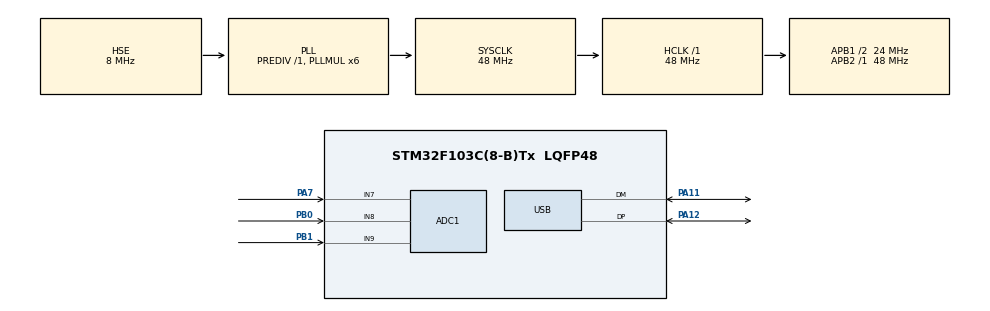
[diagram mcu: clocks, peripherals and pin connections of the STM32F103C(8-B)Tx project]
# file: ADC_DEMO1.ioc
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Mcu.Family=STM32F1
RCC.PLLSourceVirtual=RCC_PLLSOURCE_HSE
USB_DEVICE.CLASS_NAME_FS=CDC
Dma.ADC1.0.Instance=DMA1_Channel1
ADC1.Rank-0\#ChannelRegularConversion=1
PD1-OSC_OUT.Mode=HSE-External-Oscillator
ADC1.ContinuousConvMode=ENABLE
USB_DEVICE.VirtualModeFS=Cdc_FS
PA11.Mode=Device
PD0-OSC_IN.Signal=RCC_OSC_IN
RCC.APB1CLKDivider=RCC_HCLK_DIV2
ADC1.SamplingTime-2\#ChannelRegularConversion=ADC_SAMPLETIME_55CYCLES_5
RCC.SYSCLKSource=RCC_SYSCLKSOURCE_PLLCLK
ProjectManager.StackSize=0x400
PD1-OSC_OUT.Signal=RCC_OSC_OUT
RCC.ADCPresc=RCC_ADCPCLK2_DIV4
PA13.Signal=SYS_JTMS-SWDIO
Dma.ADC1.0.PeriphDataAlignment=DMA_PDATAALIGN_WORD
PA12.Signal=USB_DP
ProjectManager.TargetToolchain=STM32CubeIDE
Dma.ADC1.0.Mode=DMA_CIRCULAR
SH.ADCx_IN7.0=ADC1_IN7,IN7
RCC.HCLKFreq_Value=48000000
VP_USB_DEVICE_VS_USB_DEVICE_CDC_FS.Mode=CDC_FS
Dma.ADC1.0.Priority=DMA_PRIORITY_MEDIUM
RCC.APB2TimFreq_Value=48000000
ADC1.Channel-1\#ChannelRegularConversion=ADC_CHANNEL_9
Dma.ADC1.0.Direction=DMA_PERIPH_TO_MEMORY
ADC1.Channel-2\#ChannelRegularConversion=ADC_CHANNEL_7
RCC.USBFreq_Value=48000000
Dma.ADC1.0.MemDataAlignment=DMA_MDATAALIGN_WORD
RCC.AHBFreq_Value=48000000
PD0-OSC_IN.Mode=HSE-External-Oscillator
ADC1.Channel-0\#ChannelRegularConversion=ADC_CHANNEL_8
board=custom
RCC.PLLMUL=RCC_PLL_MUL6
RCC.APB2Freq_Value=48000000
ADC1.Rank-2\#ChannelRegularConversion=3
PA14.Mode=Serial_Wire
Dma.ADC1.0.PeriphInc=DMA_PINC_DISABLE
NVIC.USB_LP_CAN1_RX0_IRQn=true\:0\:0\:false\:false\:true\:false\:true
SH.ADCx_IN8.0=ADC1_IN8,IN8
ADC1.NbrOfConversion=3
PA13.Mode=Serial_Wire
Mcu.Name=STM32F103C(8-B)Tx
ADC1.SamplingTime-0\#ChannelRegularConversion=ADC_SAMPLETIME_55CYCLES_5
ADC1.SamplingTime-1\#ChannelRegularConversion=ADC_SAMPLETIME_55CYCLES_5
RCC.SYSCLKFreq_VALUE=48000000
Mcu.Package=LQFP48
PB1.Signal=ADCx_IN9
ADC1.master=1
PA12.Mode=Device
ADC1.Rank-1\#ChannelRegularConversion=2
PA11.Signal=USB_DM
PA14.Signal=SYS_JTCK-SWCLK
Dma.ADC1.0.MemInc=DMA_MINC_ENABLE
ProjectManager.HeapSize=0x200
SH.ADCx_IN9.0=ADC1_IN9,IN9
NVIC.PriorityGroup=NVIC_PRIORITYGROUP_4
ADC1.NbrOfConversionFlag=1
RCC.APB1TimFreq_Value=48000000
NVIC.DMA1_Channel1_IRQn=true\:0\:0\:false\:false\:true\:false\:true
Dma.Request0=ADC1
RCC.APB1Freq_Value=24000000
PB0.Signal=ADCx_IN8
USB_DEVICE.VirtualMode=Cdc
PA7.Signal=ADCx_IN7

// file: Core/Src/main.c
/* USER CODE BEGIN Header */
/**
  ******************************************************************************
  * @file           : main.c
  * @brief          : Main program body
  ******************************************************************************
  * @attention
  *
  * <h2><center>&copy; Copyright (c) 2021 STMicroelectronics.
  * All rights reserved.</center></h2>
  *
  * This software component is licensed by ST under BSD 3-Clause license,
  * the "License"; You may not use this file except in compliance with the
  * License. You may obtain a copy of the License at:
  *                        opensource.org/licenses/BSD-3-Clause
  *
  ******************************************************************************
  */
/* USER CODE END Header */
#include "main.h"
#include "usb_device.h"
#include "simulation.h"

ADC_HandleTypeDef hadc1;
DMA_HandleTypeDef hdma_adc1;

void SystemClock_Config(void);
static void MX_GPIO_Init(void);
static void MX_DMA_Init(void);
static void MX_ADC1_Init(void);

/* USER CODE BEGIN 0 */
ts_user_input user_data;
uint32_t adc_buffer[3] = {0};
char buffer[160] = {0};

void HAL_ADC_ConvCpltCallback(ADC_HandleTypeDef* hadc)
{
	if(hadc->Instance == ADC1)
	{
		user_data.ileri = adc_buffer[0];
		user_data.geri = adc_buffer[1];
		user_data.direksiyon = adc_buffer[2];
	}
}
/* USER CODE END 0 */

int main(void)
{
  /* USER CODE BEGIN 1 */
	char buffer_send[512] = {0};
	char temp[64] = {0};
  /* USER CODE END 1 */

  /* MCU Configuration--------------------------------------------------------*/

  /* Reset of all peripherals, Initializes the Flash interface and the Systick. */
  HAL_Init();

  /* Configure the system clock */
  SystemClock_Config();

  /* Initialize all configured peripherals */
  MX_GPIO_Init();
  MX_DMA_Init();
  MX_ADC1_Init();
  MX_USB_DEVICE_Init();
  /* USER CODE BEGIN 2 */
  HAL_ADC_Start_DMA(&hadc1, adc_buffer, 3);
  /* USER CODE END 2 */
  /* Infinite loop */
  /* USER CODE BEGIN WHILE */
  while (1)
  {
	  CDC_Transmit_FS(&user_data, sizeof(ts_user_input));

	  HAL_Delay(500);
    /* USER CODE END WHILE */

  }
}

void SystemClock_Config(void)
{
  RCC_OscInitTypeDef RCC_OscInitStruct = {0};
  RCC_ClkInitTypeDef RCC_ClkInitStruct = {0};
  RCC_PeriphCLKInitTypeDef PeriphClkInit = {0};

  /** Initializes the RCC Oscillators according to the specified parameters
  * in the RCC_OscInitTypeDef structure.
  */
  RCC_OscInitStruct.OscillatorType = RCC_OSCILLATORTYPE_HSE;
  RCC_OscInitStruct.HSEState = RCC_HSE_ON;
  RCC_OscInitStruct.HSEPredivValue = RCC_HSE_PREDIV_DIV1;
  RCC_OscInitStruct.HSIState = RCC_HSI_ON;
  RCC_OscInitStruct.PLL.PLLState = RCC_PLL_ON;
  RCC_OscInitStruct.PLL.PLLSource = RCC_PLLSOURCE_HSE;
  RCC_OscInitStruct.PLL.PLLMUL = RCC_PLL_MUL6;
  if (HAL_RCC_OscConfig(&RCC_OscInitStruct) != HAL_OK)
  {
    Error_Handler();
  }
  /** Initializes the CPU, AHB and APB buses clocks
  */
  RCC_ClkInitStruct.ClockType = RCC_CLOCKTYPE_HCLK|RCC_CLOCKTYPE_SYSCLK
                              |RCC_CLOCKTYPE_PCLK1|RCC_CLOCKTYPE_PCLK2;
  RCC_ClkInitStruct.SYSCLKSource = RCC_SYSCLKSOURCE_PLLCLK;
  RCC_ClkInitStruct.AHBCLKDivider = RCC_SYSCLK_DIV1;
  RCC_ClkInitStruct.APB1CLKDivider = RCC_HCLK_DIV2;
  RCC_ClkInitStruct.APB2CLKDivider = RCC_HCLK_DIV1;

  if (HAL_RCC_ClockConfig(&RCC_ClkInitStruct, FLASH_LATENCY_1) != HAL_OK)
  {
    Error_Handler();
  }
  PeriphClkInit.PeriphClockSelection = RCC_PERIPHCLK_ADC|RCC_PERIPHCLK_USB;
  PeriphClkInit.AdcClockSelection = RCC_ADCPCLK2_DIV4;
  PeriphClkInit.UsbClockSelection = RCC_USBCLKSOURCE_PLL;
  if (HAL_RCCEx_PeriphCLKConfig(&PeriphClkInit) != HAL_OK)
  {
    Error_Handler();
  }
}

static void MX_ADC1_Init(void)
{

  ADC_ChannelConfTypeDef sConfig = {0};

  /** Common config
  */
  hadc1.Instance = ADC1;
  hadc1.Init.ScanConvMode = ADC_SCAN_ENABLE;
  hadc1.Init.ContinuousConvMode = ENABLE;
  hadc1.Init.DiscontinuousConvMode = DISABLE;
  hadc1.Init.ExternalTrigConv = ADC_SOFTWARE_START;
  hadc1.Init.DataAlign = ADC_DATAALIGN_RIGHT;
  hadc1.Init.NbrOfConversion = 3;
  if (HAL_ADC_Init(&hadc1) != HAL_OK)
  {
    Error_Handler();
  }
  /** Configure Regular Channel
  */
  sConfig.Channel = ADC_CHANNEL_8;
  sConfig.Rank = ADC_REGULAR_RANK_1;
  sConfig.SamplingTime = ADC_SAMPLETIME_55CYCLES_5;
  if (HAL_ADC_ConfigChannel(&hadc1, &sConfig) != HAL_OK)
  {
    Error_Handler();
  }
  /** Configure Regular Channel
  */
  sConfig.Channel = ADC_CHANNEL_9;
  sConfig.Rank = ADC_REGULAR_RANK_2;
  if (HAL_ADC_ConfigChannel(&hadc1, &sConfig) != HAL_OK)
  {
    Error_Handler();
  }
  /** Configure Regular Channel
  */
  sConfig.Channel = ADC_CHANNEL_7;
  sConfig.Rank = ADC_REGULAR_RANK_3;
  if (HAL_ADC_ConfigChannel(&hadc1, &sConfig) != HAL_OK)
  {
    Error_Handler();
  }

}

static void MX_DMA_Init(void)
{

  /* DMA controller clock enable */
  __HAL_RCC_DMA1_CLK_ENABLE();

  /* DMA interrupt init */
  /* DMA1_Channel1_IRQn interrupt configuration */
  HAL_NVIC_SetPriority(DMA1_Channel1_IRQn, 0, 0);
  HAL_NVIC_EnableIRQ(DMA1_Channel1_IRQn);

}

static void MX_GPIO_Init(void)
{

  /* GPIO Ports Clock Enable */
  __HAL_RCC_GPIOD_CLK_ENABLE();
  __HAL_RCC_GPIOA_CLK_ENABLE();
  __HAL_RCC_GPIOB_CLK_ENABLE();

}

void Error_Handler(void)
{
  __disable_irq();
  while (1)
  {
  }
}

/************************ (C) COPYRIGHT STMicroelectronics *****END OF FILE****/
